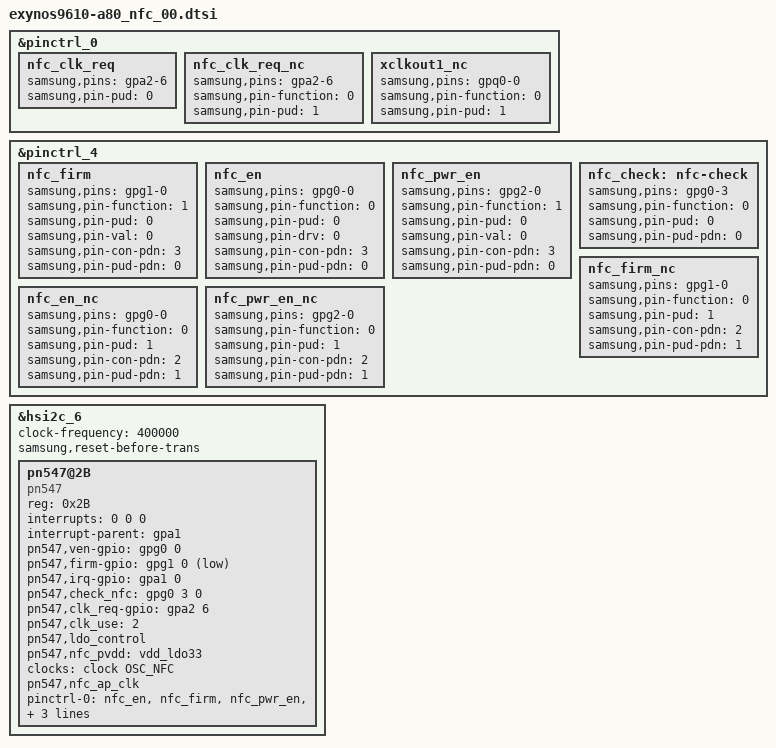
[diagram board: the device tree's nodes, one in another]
/* Copyright (c) 2013, Samsung Electronics Corporation. All rights reserved.
 *
 * This program is free software; you can redistribute it and/or modify
 * it under the terms of the GNU General Public License version 2 and
 * only version 2 as published by the Free Software Foundation.
 *
 * This program is distributed in the hope that it will be useful,
 * but WITHOUT ANY WARRANTY; without even the implied warranty of
 * MERCHANTABILITY or FITNESS FOR A PARTICULAR PURPOSE.  See the
 * GNU General Public License for more details.
 */

&pinctrl_0 {
	nfc_clk_req: nfc_clk_req {
		samsung,pins = "gpa2-6";
		samsung,pin-pud = <0>;
	 };

	nfc_clk_req_nc: nfc_clk_req_nc {
		samsung,pins = "gpa2-6";
		samsung,pin-function = <0>;
		samsung,pin-pud = <1>;
	 };

	xclkout1_nc: xclkout1_nc {
		samsung,pins = "gpq0-0";
		samsung,pin-function = <0>;
		samsung,pin-pud = <1>;
	};
};

&pinctrl_4 {
	nfc_firm: nfc_firm {
		samsung,pins = "gpg1-0";
		samsung,pin-function = <1>;
		samsung,pin-pud = <0>;
		samsung,pin-val = <0>;
		samsung,pin-con-pdn = <3>;
		samsung,pin-pud-pdn = <0>;
	};

	nfc_en: nfc_en {
		samsung,pins = "gpg0-0";
		samsung,pin-function = <0>;
		samsung,pin-pud = <0>;
		samsung,pin-drv = <0>;
		samsung,pin-con-pdn = <3>;
		samsung,pin-pud-pdn = <0>;
	};

	nfc_pwr_en: nfc_pwr_en {
		samsung,pins = "gpg2-0";
		samsung,pin-function = <1>;
		samsung,pin-pud = <0>;
		samsung,pin-val = <0>;
		samsung,pin-con-pdn = <3>;
		samsung,pin-pud-pdn = <0>;
	};

	nfc_check: nfc-check {
		samsung,pins = "gpg0-3";
		samsung,pin-function = <0>;
		samsung,pin-pud = <0>;
		samsung,pin-pud-pdn = <0>;
	};

	nfc_firm_nc: nfc_firm_nc {
		samsung,pins = "gpg1-0";
		samsung,pin-function = <0>;
		samsung,pin-pud = <1>;
		samsung,pin-con-pdn = <2>;
		samsung,pin-pud-pdn = <1>;
	};

	nfc_en_nc: nfc_en_nc {
		samsung,pins = "gpg0-0";
		samsung,pin-function = <0>;
		samsung,pin-pud = <1>;
		samsung,pin-con-pdn = <2>;
		samsung,pin-pud-pdn = <1>;
	};

	nfc_pwr_en_nc: nfc_pwr_en_nc {
		samsung,pins = "gpg2-0";
		samsung,pin-function = <0>;
		samsung,pin-pud = <1>;
		samsung,pin-con-pdn = <2>;
		samsung,pin-pud-pdn = <1>;
	};
};

/* USI_2_CMGP */
&hsi2c_6 {
	#address-cells = <1>;
	#size-cells = <0>;
	status = "okay";
	clock-frequency = <400000>;
	samsung,reset-before-trans;

	pn547@2B {
		compatible = "pn547";
		reg = <0x2B>;

		interrupts = <0 0 0>;
		interrupt-parent = <&gpa1>;

		pn547,ven-gpio = <&gpg0 0 0>;
		pn547,firm-gpio = <&gpg1 0 1>;
		pn547,irq-gpio = <&gpa1 0 0>;
		pn547,check_nfc = <&gpg0 3 0>;
		pn547,clk_req-gpio = <&gpa2 6 0>;
		pn547,clk_use = <2>;

		pn547,ldo_control;
		pn547,nfc_pvdd = "vdd_ldo33";

		clocks = <&clock OSC_NFC>;
		clock-names = "oscclk_nfc";
		pn547,nfc_ap_clk;

		pinctrl-names = "default", "nfc_nc";
		pinctrl-0 = <&nfc_en &nfc_firm &nfc_pwr_en &xclkout1 &nfc_clk_req &nfc_check>;
		pinctrl-1 = <&nfc_en_nc &nfc_firm_nc &nfc_pwr_en_nc &nfc_clk_req_nc &xclkout1_nc>;
	};
};
